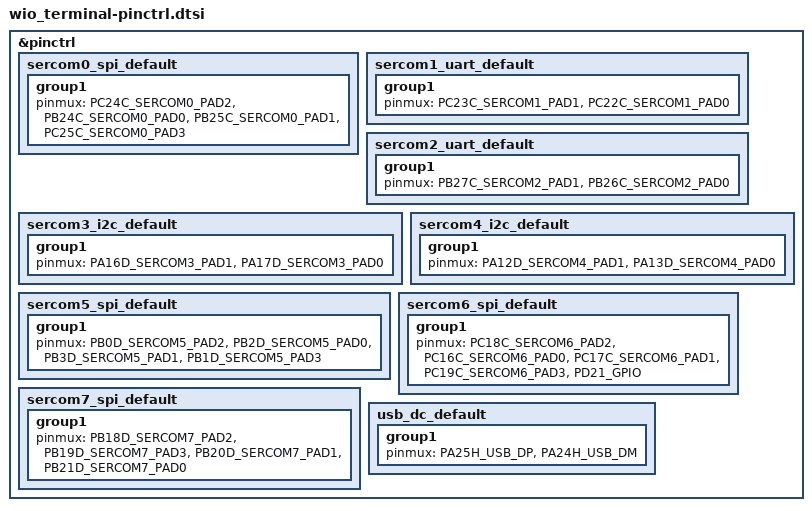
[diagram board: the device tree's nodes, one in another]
/*
 * Copyright (c) 2023, Benjamin Cabé <benjamin@zephyrproject.org>
 * SPDX-License-Identifier: Apache-2.0
 */

#include <dt-bindings/pinctrl/samd51p-pinctrl.h>

&pinctrl {

	sercom0_spi_default: sercom0_spi_default {
		group1 {
			pinmux = <PC24C_SERCOM0_PAD2>,	// MISO
				 <PB24C_SERCOM0_PAD0>,		// MOSI
				 <PB25C_SERCOM0_PAD1>,		// SCK	
				 <PC25C_SERCOM0_PAD3>;		// SS
		};
	};

	sercom1_uart_default: sercom1_uart_default {
		group1 {
			pinmux = <PC23C_SERCOM1_PAD1>,
				 <PC22C_SERCOM1_PAD0>;
		};
	};

	sercom2_uart_default: sercom2_uart_default {
		group1 {
			pinmux = <PB27C_SERCOM2_PAD1>,
				 <PB26C_SERCOM2_PAD0>;
		};
	};

	sercom3_i2c_default: sercom3_i2c_default {
		group1 {
			pinmux = <PA16D_SERCOM3_PAD1>,
				 <PA17D_SERCOM3_PAD0>;
		};
	};
	
	sercom4_i2c_default: sercom4_i2c_default {
		group1 {
			pinmux = <PA12D_SERCOM4_PAD1>,
				 <PA13D_SERCOM4_PAD0>;
		};
	};
	
	sercom5_spi_default: sercom5_spi_default {
		group1 {
			pinmux = <PB0D_SERCOM5_PAD2>,	// MISO
				 <PB2D_SERCOM5_PAD0>,		// MOSI
				 <PB3D_SERCOM5_PAD1>,		// SCK	
				 <PB1D_SERCOM5_PAD3>;		// SS
		};
	};

	sercom6_spi_default: sercom6_spi_default {
		group1 {
			pinmux = <PC18C_SERCOM6_PAD2>,	// MISO
				 <PC16C_SERCOM6_PAD0>,		// MOSI
				 <PC17C_SERCOM6_PAD1>,		// SCK	
				 <PC19C_SERCOM6_PAD3>,		// SS
				 <PD21_GPIO>;				// SD_DET
		};
	};

	sercom7_spi_default: sercom7_spi_default {
		group1 {
			pinmux = <PB18D_SERCOM7_PAD2>,	// MISO
				 <PB19D_SERCOM7_PAD3>,		// MOSI
				 <PB20D_SERCOM7_PAD1>,		// SCK	
				 <PB21D_SERCOM7_PAD0>;		// SS
		};
	};

	usb_dc_default: usb_dc_default {
		group1 {
			pinmux = <PA25H_USB_DP>,
				 <PA24H_USB_DM>;
		};
	};

};
